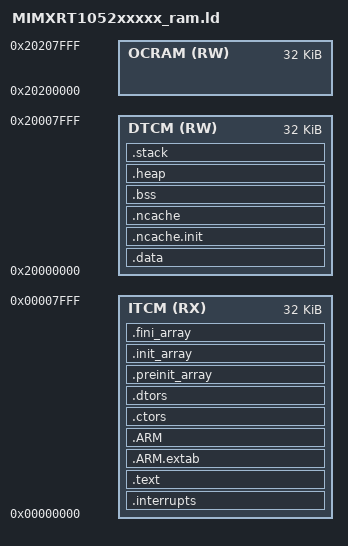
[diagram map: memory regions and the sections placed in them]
/*
** ###################################################################
**     Processors:          MIMXRT1052CVJ5B
**                          MIMXRT1052CVL5B
**                          MIMXRT1052DVJ6B
**                          MIMXRT1052DVL6B
**
**     Compiler:            GNU C Compiler
**     Reference manual:    IMXRT1050RM Rev.2.1, 12/2018 | IMXRT1050SRM Rev.2
**     Version:             rev. 1.0, 2018-09-21
**     Build:               b210709
**
**     Abstract:
**         Linker file for the GNU C Compiler
**
**     Copyright 2016 Freescale Semiconductor, Inc.
**     Copyright 2016-2021 NXP
**     All rights reserved.
**
**     SPDX-License-Identifier: BSD-3-Clause
**
**     http:                 www.nxp.com
**     mail:                 support@nxp.com
**
** ###################################################################
*/

/* Entry Point */
ENTRY(Reset_Handler)

HEAP_SIZE  = DEFINED(__heap_size__)  ? __heap_size__  : 0x0400;
STACK_SIZE = DEFINED(__stack_size__) ? __stack_size__ : 0x0400;

/* Specify the memory areas */
MEMORY
{
  /* Default FlexRAM partition when ship to user */
  ITCM                 (RX)  : ORIGIN = 0x00000000, LENGTH = 32K /* Default 128KB */
  DTCM                 (RW)  : ORIGIN = 0x20000000, LENGTH = 32K /* Default 128KB */
  OCRAM                (RW)  : ORIGIN = 0x20200000, LENGTH = 32K /* Default 256KB */
}

/* Define output sections */
SECTIONS
{
  __NCACHE_REGION_START = ORIGIN(OCRAM);
  __NCACHE_REGION_SIZE  = 0;

  /* The startup code goes first into internal RAM */
  .interrupts :
  {
    __VECTOR_TABLE = .;
    __Vectors = .;
    . = ALIGN(4);
    KEEP(*(.isr_vector))     /* Startup code */
    . = ALIGN(4);
  } > ITCM

  /* The program code and other data goes into internal RAM */
  .text :
  {
    . = ALIGN(4);
    *(.text)                 /* .text sections (code) */
    *(.text*)                /* .text* sections (code) */
    *(.rodata)               /* .rodata sections (constants, strings, etc.) */
    *(.rodata*)              /* .rodata* sections (constants, strings, etc.) */
    *(CodeQuickAccess)       /* quick access code section */
    *(.glue_7)               /* glue arm to thumb code */
    *(.glue_7t)              /* glue thumb to arm code */
    *(.eh_frame)
    KEEP (*(.init))
    KEEP (*(.fini))
    . = ALIGN(4);
  } > ITCM

  .ARM.extab :
  {
    *(.ARM.extab* .gnu.linkonce.armextab.*)
  } > ITCM

  .ARM :
  {
    __exidx_start = .;
    *(.ARM.exidx*)
    __exidx_end = .;
  } > ITCM

 .ctors :
  {
    __CTOR_LIST__ = .;
    /* gcc uses crtbegin.o to find the start of
       the constructors, so we make sure it is
       first.  Because this is a wildcard, it
       doesn't matter if the user does not
       actually link against crtbegin.o; the
       linker won't look for a file to match a
       wildcard.  The wildcard also means that it
       doesn't matter which directory crtbegin.o
       is in.  */
    KEEP (*crtbegin.o(.ctors))
    KEEP (*crtbegin?.o(.ctors))
    /* We don't want to include the .ctor section from
       from the crtend.o file until after the sorted ctors.
       The .ctor section from the crtend file contains the
       end of ctors marker and it must be last */
    KEEP (*(EXCLUDE_FILE(*crtend?.o *crtend.o) .ctors))
    KEEP (*(SORT(.ctors.*)))
    KEEP (*(.ctors))
    __CTOR_END__ = .;
  } > ITCM

  .dtors :
  {
    __DTOR_LIST__ = .;
    KEEP (*crtbegin.o(.dtors))
    KEEP (*crtbegin?.o(.dtors))
    KEEP (*(EXCLUDE_FILE(*crtend?.o *crtend.o) .dtors))
    KEEP (*(SORT(.dtors.*)))
    KEEP (*(.dtors))
    __DTOR_END__ = .;
  } > ITCM

  .preinit_array :
  {
    PROVIDE_HIDDEN (__preinit_array_start = .);
    KEEP (*(.preinit_array*))
    PROVIDE_HIDDEN (__preinit_array_end = .);
  } > ITCM

  .init_array :
  {
    PROVIDE_HIDDEN (__init_array_start = .);
    KEEP (*(SORT(.init_array.*)))
    KEEP (*(.init_array*))
    PROVIDE_HIDDEN (__init_array_end = .);
  } > ITCM

  .fini_array :
  {
    PROVIDE_HIDDEN (__fini_array_start = .);
    KEEP (*(SORT(.fini_array.*)))
    KEEP (*(.fini_array*))
    PROVIDE_HIDDEN (__fini_array_end = .);
  } > ITCM

  __etext = .;    /* define a global symbol at end of code */
  __DATA_ROM = .; /* Symbol is used by startup for data initialization */

  __VECTOR_RAM = ORIGIN(ITCM);
  __RAM_VECTOR_TABLE_SIZE_BYTES = 0x0;

  .data : AT(__DATA_ROM)
  {
    . = ALIGN(4);
    __DATA_RAM = .;
    __data_start__ = .;      /* create a global symbol at data start */
    *(m_usb_dma_init_data)
    *(.data)                 /* .data sections */
    *(.data*)                /* .data* sections */
    *(DataQuickAccess)       /* quick access data section */
    KEEP(*(.jcr*))
    . = ALIGN(4);
    __data_end__ = .;        /* define a global symbol at data end */
  } > DTCM

  __NDATA_ROM = __DATA_ROM + (__data_end__ - __data_start__);
  .ncache.init : AT(__NDATA_ROM)
  {
    __noncachedata_start__ = .;   /* create a global symbol at ncache data start */
    *(NonCacheable.init)
    . = ALIGN(4);
    __noncachedata_init_end__ = .;   /* create a global symbol at initialized ncache data end */
  } > DTCM
  . = __noncachedata_init_end__;
  .ncache :
  {
    *(NonCacheable)
    . = ALIGN(4);
    __noncachedata_end__ = .;     /* define a global symbol at ncache data end */
  } > DTCM

  __DATA_END = __NDATA_ROM + (__noncachedata_init_end__ - __noncachedata_start__);
  text_end = ORIGIN(ITCM) + LENGTH(ITCM);
  ASSERT(__DATA_END <= text_end, "region ITCM overflowed with text and data")

  /* Uninitialized data section */
  .bss :
  {
    /* This is used by the startup in order to initialize the .bss section */
    . = ALIGN(4);
    __START_BSS = .;
    __bss_start__ = .;
    *(m_usb_dma_noninit_data)
    *(.bss)
    *(.bss*)
    *(COMMON)
    . = ALIGN(4);
    __bss_end__ = .;
    __END_BSS = .;
  } > DTCM

  .heap :
  {
    . = ALIGN(8);
    __end__ = .;
    PROVIDE(end = .);
    __HeapBase = .;
    . += HEAP_SIZE;
    __HeapLimit = .;
    __heap_limit = .; /* Add for _sbrk */
  } > DTCM

  .stack :
  {
    . = ALIGN(8);
    . += STACK_SIZE;
  } > DTCM

  /* Initializes stack on the end of block */
  __StackTop   = ORIGIN(DTCM) + LENGTH(DTCM);
  __StackLimit = __StackTop - STACK_SIZE;
  PROVIDE(__stack = __StackTop);

  .ARM.attributes 0 : { *(.ARM.attributes) }

  ASSERT(__StackLimit >= __HeapLimit, "region DTCM overflowed with stack and heap")
}
